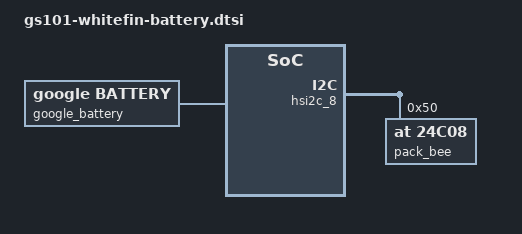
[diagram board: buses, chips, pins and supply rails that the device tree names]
// SPDX-License-Identifier: GPL-2.0-only
/*
 * Battery device tree entries specific to Whitefin
 *
 * Copyright 2020 Google,LLC
 *
 */

/ {
  fragment@battery {
    target-path = "/";
      __overlay__ {

	google_battery: google,battery {
		status = "okay";
		compatible = "google,battery";
		#cooling-cells = <2>;
		google,fg-psy-name = "maxfg";

		google,chg-battery-capacity = <4000>;

		/* charge table */
		google,chg-temp-limits = <0 100 200 420 460 480 550>;
		google,chg-cv-limits = <4200000 4300000 4400000>;
		google,chg-cc-limits = <
			30  10   0
			50  30  30
			100  70  50
			80  50  50
			50  50   0
			30   0   0
		>;
		#thermal-sensor-cells = <0>;
	};

	google_cpm: google,cpm {
		status = "okay";
		compatible = "google,cpm";
		google,chg-power-supplies = "main-charger";
	};

	google_charger: google,charger {
		status = "okay";
		compatible = "google,charger";
		#cooling-cells = <2>;

		google,chg-power-supply = "gcpm";
		google,bat-power-supply = "battery";
		google,usb-power-supply = "usb";

		google,fv-max-uv = <4400000>;

		google,thermal-mitigation = <4000000 3000000
					2000000 1000000 500000>;
		google,wlc-thermal-mitigation = <1100000 500000 250000 110000>;
		google,therm-wlc-overrides-fcc;
	};

	google_bms {
		nvmem = <&pack_bee>;
		nvmem-names = "5-00500";
		/* pack eeprom is available only with P20+ batteries */
		google,bee-name = "5-00500";
	};

    };
  };
};

&hsi2c_8 {
	#address-cells = <1>;
	#size-cells = <0>;
	status = "okay";

	pinctrl-names = "default";
	pinctrl-0 = <&hsi2c8_bus>;

	pack_bee: m24c08@50 {
		status = "okay";
		compatible = "at,24c08";

		reg = <0x50>;
	};
};

&hsi2c12_bus {
	samsung,pins = "gpp23-4", "gpp23-5";
	samsung,pin-pud = <EXYNOS_PIN_PULL_UP>;
};
